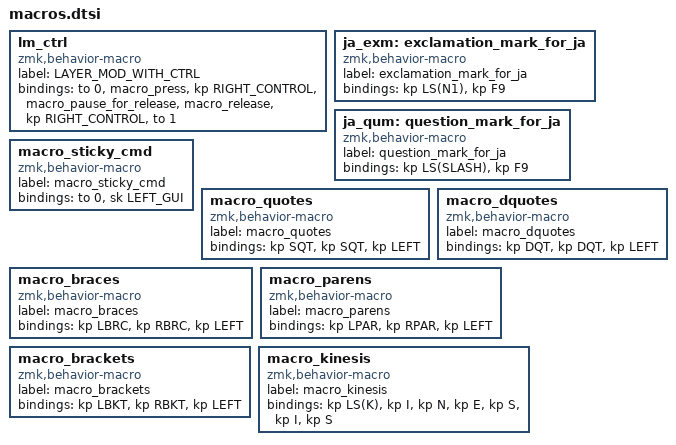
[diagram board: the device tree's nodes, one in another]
/**
 * Temporarily switches to a layer (`&mo`) while a modifier is held.
 * Analogous to QMK's `LM()`, using a parameterized macro.
 *
 * Params:
 *  1. Layer to switch to
 *  2. Modifier to press while layer is active
 *
 * Example:
 *  `&lm NUM_LAYER LSHIFT`
 */
lm_ctrl: lm_ctrl {
    label = "LAYER_MOD_WITH_CTRL";
    compatible = "zmk,behavior-macro";
    #binding-cells = <0>;
    bindings
        = <&to 0>
        , <&macro_press &kp RIGHT_CONTROL>
        , <&macro_pause_for_release>
        , <&macro_release &kp RIGHT_CONTROL>
        , <&to 1>
        ;
};

ja_exm: exclamation_mark_for_ja {
    label = "exclamation_mark_for_ja";
    compatible = "zmk,behavior-macro";
    #binding-cells = <0>;
    bindings
        = <&kp LS(N1) &kp F9>
        ;
};

ja_qum: question_mark_for_ja {
    label = "question_mark_for_ja";
    compatible = "zmk,behavior-macro";
    #binding-cells = <0>;
    bindings
        = <&kp LS(SLASH) &kp F9>
        ;
};

macro_sticky_cmd: macro_sticky_cmd{
compatible = "zmk,behavior-macro";
label = "macro_sticky_cmd";
#binding-cells = <0>;
bindings = <&to 0>, <&sk LEFT_GUI>;
};
macro_quotes: macro_quotes{
compatible = "zmk,behavior-macro";
label = "macro_quotes";
#binding-cells = <0>;
bindings = <&kp SQT>, <&kp SQT>, <&kp LEFT>;
};
macro_dquotes: macro_dquotes{
compatible = "zmk,behavior-macro";
label = "macro_dquotes";
#binding-cells = <0>;
bindings = <&kp DQT>, <&kp DQT>, <&kp LEFT>;
};
macro_braces: macro_braces{
compatible = "zmk,behavior-macro";
label = "macro_braces";
#binding-cells = <0>;
bindings = <&kp LBRC>, <&kp RBRC>, <&kp LEFT>;
};
macro_parens: macro_parens{
compatible = "zmk,behavior-macro";
label = "macro_parens";
#binding-cells = <0>;
bindings = <&kp LPAR>, <&kp RPAR>, <&kp LEFT>;
};
macro_brackets: macro_brackets{
compatible = "zmk,behavior-macro";
label = "macro_brackets";
#binding-cells = <0>;
bindings = <&kp LBKT>, <&kp RBKT>, <&kp LEFT>;
};
macro_kinesis: macro_kinesis{
compatible = "zmk,behavior-macro";
label = "macro_kinesis";
#binding-cells = <0>;
bindings = <&kp LS(K)>, <&kp I>, <&kp N>, <&kp E>, <&kp S>, <&kp I>, <&kp S>;
};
